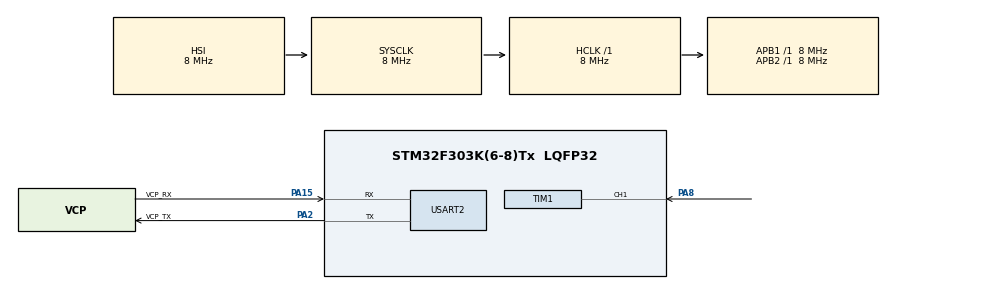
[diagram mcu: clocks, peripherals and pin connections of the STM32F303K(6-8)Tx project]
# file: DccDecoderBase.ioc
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Mcu.Family=STM32F3
Mcu.Name=STM32F303K(6-8)Tx
Mcu.Package=LQFP32
NVIC.PriorityGroup=NVIC_PRIORITYGROUP_4
NVIC.TIM1_CC_IRQn=true\:0\:0\:false\:false\:true\:true\:true
PA13.GPIO_Label=SWDIO
PA13.Mode=Serial_Wire
PA13.Signal=SYS_JTMS-SWDIO
PA14.GPIO_Label=SWCLK
PA14.Mode=Serial_Wire
PA14.Signal=SYS_JTCK-SWCLK
PA15.GPIO_Label=VCP_RX
PA15.Mode=Asynchronous
PA15.Signal=USART2_RX
PA2.GPIO_Label=VCP_TX
PA2.Mode=Asynchronous
PA2.Signal=USART2_TX
PA8.GPIO_PuPd=GPIO_PULLUP
PA8.GPIO_Speed=GPIO_SPEED_FREQ_HIGH
PA8.Signal=S_TIM1_CH1
PF0\ /\ OSC_IN.GPIO_Label=MCO
PF0\ /\ OSC_IN.Mode=HSE-External-Clock-Source
PF0\ /\ OSC_IN.Signal=RCC_OSC_IN
ProjectManager.HeapSize=0x200
ProjectManager.StackSize=0x400
ProjectManager.TargetToolchain=STM32CubeIDE
RCC.AHBFreq_Value=8000000
RCC.APB1Freq_Value=8000000
RCC.APB2Freq_Value=8000000
RCC.CortexFreq_Value=8000000
RCC.HSE_VALUE=8000000
RCC.HSI_VALUE=8000000
RCC.SYSCLKFreq_VALUE=8000000
SH.S_TIM1_CH1.0=TIM1_CH1,Input_Capture1_from_TI1
TIM1.Channel-Input_Capture1_from_TI1=TIM_CHANNEL_1
TIM1.ICFilter_CH1=0x0f
TIM1.ICPolarity_CH1=TIM_INPUTCHANNELPOLARITY_RISING
TIM1.Period=32768
TIM1.Prescaler=8
USART2.VirtualMode-Asynchronous=VM_ASYNC
VP_TIM1_VS_ClockSourceINT.Mode=Internal
board=NUCLEO-F303K8

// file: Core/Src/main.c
/* USER CODE BEGIN Header */
/**
  ******************************************************************************
  * @file           : main.c
  * @brief          : Main program body
  ******************************************************************************
  * @attention
  *
  * <h2><center>&copy; Copyright (c) 2019 STMicroelectronics.
  * All rights reserved.</center></h2>
  *
  * This software component is licensed by ST under BSD 3-Clause license,
  * the "License"; You may not use this file except in compliance with the
  * License. You may obtain a copy of the License at:
  *                        opensource.org/licenses/BSD-3-Clause
  *
  ******************************************************************************
  */
/* USER CODE END Header */

#include "main.h"

TIM_HandleTypeDef htim1;

UART_HandleTypeDef huart2;

void SystemClock_Config(void);
static void MX_GPIO_Init(void);
static void MX_USART2_UART_Init(void);
static void MX_TIM1_Init(void);

/* USER CODE BEGIN 0 */

uint8_t 	idx = 0,cutout=0, address, data , check,sync;
uint8_t		recv_bytes[8], recv_idx;
uint32_t	current_val;
enum machine_states {WAIT_FOR_SYNC, WAIT_FOR_0FLAG0, GET_BYTE, WAIT_FOR_0FLAG1 ,CLOSING_STATE};
uint8_t		state = WAIT_FOR_SYNC;

void HAL_TIM_IC_CaptureCallback(TIM_HandleTypeDef *htim)
{
	current_val=htim1.Instance->CCR1;
	htim1.Instance->CNT = 0;
	switch ( state)
	{
	case	WAIT_FOR_SYNC:
		if ((current_val > 40 ) && (current_val < 120))
		{
			sync++;
			if ( sync > 12 )
				state = WAIT_FOR_0FLAG0;
		}
		else
			sync=0;
		break;
	case	WAIT_FOR_0FLAG0:
		if ((current_val > 120 ) && (current_val < 200))
		{
			state = GET_BYTE;
			idx = 8;
			recv_idx = 0;
			recv_bytes[recv_idx]=0;
			address = data = check = 0;
		}

	case	GET_BYTE:
		if ((current_val > 40 ) && (current_val < 120))
			recv_bytes[recv_idx] |= 1 << (idx-1);
		idx --;
		if ( idx == 0)
		{
			state = WAIT_FOR_0FLAG1;
			if ( recv_idx == 0 )
				address = recv_bytes[recv_idx];
		}
		break;
	case	WAIT_FOR_0FLAG1:
		if ((current_val > 120 ) && (current_val < 200))
		{
			state = GET_BYTE;
			idx = 8;
			recv_idx ++;
			recv_bytes[recv_idx]=0;
		}
		if ((current_val > 40 ) && (current_val < 120))
		{
			check = recv_bytes[recv_idx];
			state = CLOSING_STATE;
		}
		break;
	case	CLOSING_STATE:
		state = WAIT_FOR_SYNC;
		break;

	default : state = WAIT_FOR_SYNC;
	}
}
/* USER CODE END 0 */

int main(void)
{

  /* MCU Configuration--------------------------------------------------------*/

  /* Reset of all peripherals, Initializes the Flash interface and the Systick. */
  HAL_Init();

  /* Configure the system clock */
  SystemClock_Config();

  /* Initialize all configured peripherals */
  MX_GPIO_Init();
  MX_USART2_UART_Init();
  MX_TIM1_Init();
  /* USER CODE BEGIN 2 */
  HAL_TIM_IC_Start_IT(&htim1,TIM_CHANNEL_1);
  /* USER CODE END 2 */

  /* Infinite loop */
  while (1)
  {

  }
}

void SystemClock_Config(void)
{
  RCC_OscInitTypeDef RCC_OscInitStruct = {0};
  RCC_ClkInitTypeDef RCC_ClkInitStruct = {0};
  RCC_PeriphCLKInitTypeDef PeriphClkInit = {0};

  /** Initializes the CPU, AHB and APB busses clocks
  */
  RCC_OscInitStruct.OscillatorType = RCC_OSCILLATORTYPE_HSI;
  RCC_OscInitStruct.HSIState = RCC_HSI_ON;
  RCC_OscInitStruct.HSICalibrationValue = RCC_HSICALIBRATION_DEFAULT;
  RCC_OscInitStruct.PLL.PLLState = RCC_PLL_NONE;
  if (HAL_RCC_OscConfig(&RCC_OscInitStruct) != HAL_OK)
  {
    Error_Handler();
  }
  /** Initializes the CPU, AHB and APB busses clocks
  */
  RCC_ClkInitStruct.ClockType = RCC_CLOCKTYPE_HCLK|RCC_CLOCKTYPE_SYSCLK
                              |RCC_CLOCKTYPE_PCLK1|RCC_CLOCKTYPE_PCLK2;
  RCC_ClkInitStruct.SYSCLKSource = RCC_SYSCLKSOURCE_HSI;
  RCC_ClkInitStruct.AHBCLKDivider = RCC_SYSCLK_DIV1;
  RCC_ClkInitStruct.APB1CLKDivider = RCC_HCLK_DIV1;
  RCC_ClkInitStruct.APB2CLKDivider = RCC_HCLK_DIV1;

  if (HAL_RCC_ClockConfig(&RCC_ClkInitStruct, FLASH_LATENCY_0) != HAL_OK)
  {
    Error_Handler();
  }
  PeriphClkInit.PeriphClockSelection = RCC_PERIPHCLK_TIM1;
  PeriphClkInit.Tim1ClockSelection = RCC_TIM1CLK_HCLK;
  if (HAL_RCCEx_PeriphCLKConfig(&PeriphClkInit) != HAL_OK)
  {
    Error_Handler();
  }
}

static void MX_TIM1_Init(void)
{

  TIM_ClockConfigTypeDef sClockSourceConfig = {0};
  TIM_MasterConfigTypeDef sMasterConfig = {0};
  TIM_IC_InitTypeDef sConfigIC = {0};

  htim1.Instance = TIM1;
  htim1.Init.Prescaler = 8;
  htim1.Init.CounterMode = TIM_COUNTERMODE_UP;
  htim1.Init.Period = 32768;
  htim1.Init.ClockDivision = TIM_CLOCKDIVISION_DIV1;
  htim1.Init.RepetitionCounter = 0;
  htim1.Init.AutoReloadPreload = TIM_AUTORELOAD_PRELOAD_DISABLE;
  if (HAL_TIM_Base_Init(&htim1) != HAL_OK)
  {
    Error_Handler();
  }
  sClockSourceConfig.ClockSource = TIM_CLOCKSOURCE_INTERNAL;
  if (HAL_TIM_ConfigClockSource(&htim1, &sClockSourceConfig) != HAL_OK)
  {
    Error_Handler();
  }
  if (HAL_TIM_IC_Init(&htim1) != HAL_OK)
  {
    Error_Handler();
  }
  sMasterConfig.MasterOutputTrigger = TIM_TRGO_RESET;
  sMasterConfig.MasterOutputTrigger2 = TIM_TRGO2_RESET;
  sMasterConfig.MasterSlaveMode = TIM_MASTERSLAVEMODE_DISABLE;
  if (HAL_TIMEx_MasterConfigSynchronization(&htim1, &sMasterConfig) != HAL_OK)
  {
    Error_Handler();
  }
  sConfigIC.ICPolarity = TIM_INPUTCHANNELPOLARITY_RISING;
  sConfigIC.ICSelection = TIM_ICSELECTION_DIRECTTI;
  sConfigIC.ICPrescaler = TIM_ICPSC_DIV1;
  sConfigIC.ICFilter = 0x0f;
  if (HAL_TIM_IC_ConfigChannel(&htim1, &sConfigIC, TIM_CHANNEL_1) != HAL_OK)
  {
    Error_Handler();
  }

}

static void MX_USART2_UART_Init(void)
{

  huart2.Instance = USART2;
  huart2.Init.BaudRate = 38400;
  huart2.Init.WordLength = UART_WORDLENGTH_8B;
  huart2.Init.StopBits = UART_STOPBITS_1;
  huart2.Init.Parity = UART_PARITY_NONE;
  huart2.Init.Mode = UART_MODE_TX_RX;
  huart2.Init.HwFlowCtl = UART_HWCONTROL_NONE;
  huart2.Init.OverSampling = UART_OVERSAMPLING_16;
  huart2.Init.OneBitSampling = UART_ONE_BIT_SAMPLE_DISABLE;
  huart2.AdvancedInit.AdvFeatureInit = UART_ADVFEATURE_NO_INIT;
  if (HAL_UART_Init(&huart2) != HAL_OK)
  {
    Error_Handler();
  }

}

static void MX_GPIO_Init(void)
{

  /* GPIO Ports Clock Enable */
  __HAL_RCC_GPIOF_CLK_ENABLE();
  __HAL_RCC_GPIOA_CLK_ENABLE();

}

void Error_Handler(void)
{
}

/************************ (C) COPYRIGHT STMicroelectronics *****END OF FILE****/
